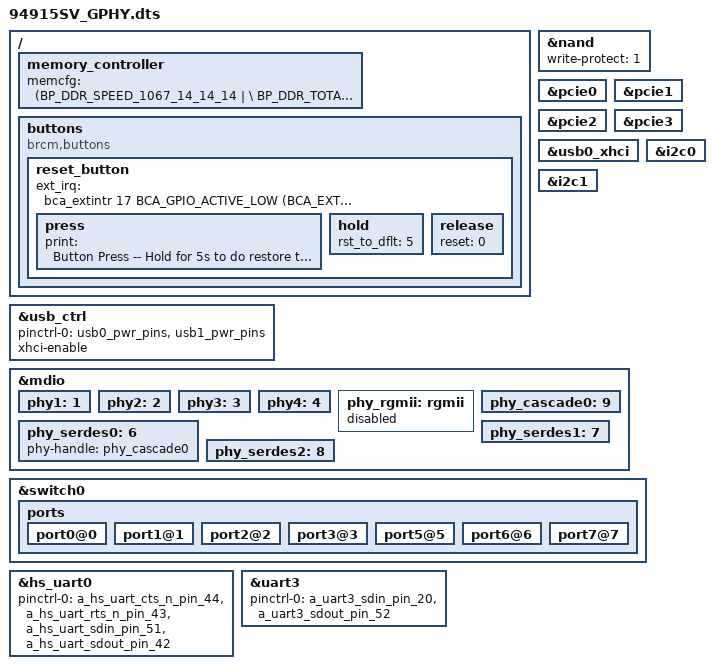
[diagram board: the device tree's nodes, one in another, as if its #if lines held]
#include "4912.dtsi"

/ {
	memory_controller {
		memcfg = <(BP_DDR_SPEED_1067_14_14_14 | \
			BP_DDR_TOTAL_SIZE_1024MB      | \
			BP_DDR_DEVICE_WIDTH_16        | \
			BP_DDR_TOTAL_WIDTH_32BIT      | \
			BP_DDR_4912_DEFAULT)>;
	};

	buttons {
		compatible = "brcm,buttons";
		reset_button {
			ext_irq = <&bca_extintr 17 BCA_GPIO_ACTIVE_LOW (BCA_EXTINTR_TYPE_LOW_LEVEL | BCA_EXTINTR_TYPE_SENSE_EDGE)>;
			press {
				print = "Button Press -- Hold for 5s to do restore to default";
			};
			hold {
				rst_to_dflt = <5>;
			};
			release {
				reset = <0>;
			};	
		};
	};
};

&nand {
	write-protect = <1>;
};

#if defined(CONFIG_BCM_PCIE_HCD) || defined(CONFIG_BCM_PCIE_HCD_MODULE)
&pcie0 {
	status = "okay";
};
&pcie1 {
	status = "okay";
};
&pcie2 {
	status = "okay";
};
&pcie3 {
	status = "okay";
};
#endif //#if defined(CONFIG_BCM_PCIE_HCD) || defined(CONFIG_BCM_PCIE_HCD_MODULE)

&usb_ctrl {
	pinctrl-names = "default";
	pinctrl-0 = <&usb0_pwr_pins &usb1_pwr_pins>;
	status = "okay";
	xhci-enable;
};
&usb0_xhci {
	status = "okay";
};

&i2c0 {
	status = "okay";
};
&i2c1 {
	status = "okay";
};

&mdio {
	phy1:1 {
		status = "okay";
	};

	phy2:2 {
		status = "okay";
	};

	phy3:3 {
		status = "okay";
	};

	phy4:4 {
		status = "okay";
	};

	phy_rgmii: rgmii {
		status = "disabled";
	};

	phy_cascade0:9 {
		status = "okay";
	};

	phy_serdes0:6 {
		phy-handle = <&phy_cascade0>;
		status = "okay";
	};

	phy_serdes1:7 {
		status = "okay";
	};

	phy_serdes2:8 {
		status = "okay";
	};
};

&switch0 {
	ports {
		port0@0 {
			status = "okay";
		};

		port1@1 {
			status = "okay";
		};

		port2@2 {
			status = "okay";
		};

		port3@3 {
			status = "okay";
		};

		port5@5 {
			status = "okay";
		};

		port6@6 {
			status = "okay";
		};

		port7@7 {
			status = "okay";
		};
	};
};
&hs_uart0 {
	pinctrl-names = "default";
	pinctrl-0 = <&a_hs_uart_cts_n_pin_44 &a_hs_uart_rts_n_pin_43 &a_hs_uart_sdin_pin_51 &a_hs_uart_sdout_pin_42 >;
	status = "okay";
};

&uart3 {
	pinctrl-names = "default";
	pinctrl-0 = <&a_uart3_sdin_pin_20 &a_uart3_sdout_pin_52 >;
	status = "okay";
};
